# nRF54h20_application register map
Vendor: Nordic Semiconductor; Series: nRF54h; File version: 1
CPU: CM33 r0p4, little endian, MPU, FPU, 3 interrupt priority bits, 480 interrupts, 8 SAU regions
Registers are 32-bit, read-write, reset 0x0 unless marked. A register's access mark holds for its fields unless they carry their own. Offsets are from the block's base; [hi:lo] are bit positions; lines under a group give offsets from that group; 'fields as' and 'values as' point back to an identical list.

## GLOBAL_USBHS_NS — USBHS 0
Base 0x4F086000
Same registers: GLOBAL_USBHS_S 0x5F086000
0x00 TASKS_START wo — Start the USB peripheral.
  [0] TASKS_START
    1=Trigger task
0x04 TASKS_STOP wo — Stop the USB peripheral
  [0] TASKS_STOP
    1=Trigger task
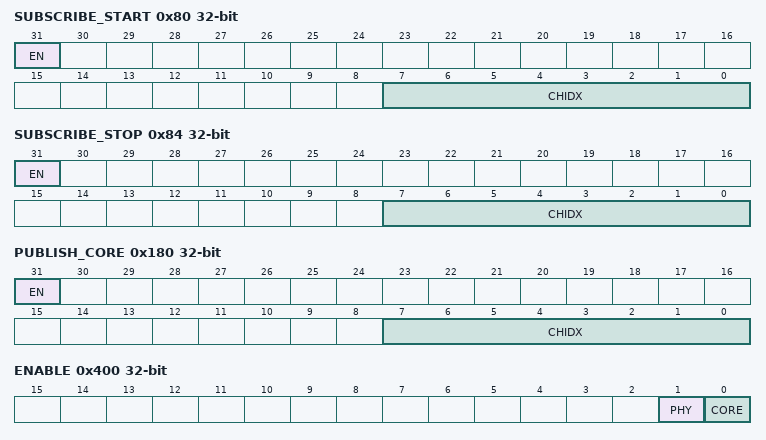
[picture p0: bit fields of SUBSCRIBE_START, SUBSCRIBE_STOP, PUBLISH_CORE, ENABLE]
0x80 SUBSCRIBE_START — Subscribe configuration for task START
  [31] EN
    0=Disabled (Disable subscription); 1=Enabled (Enable subscription)
  [7:0] CHIDX — DPPI channel that task START will subscribe to
0x84 SUBSCRIBE_STOP — Subscribe configuration for task STOP
  [31] EN
    values as SUBSCRIBE_START.EN
  [7:0] CHIDX — DPPI channel that task STOP will subscribe to
0x100 EVENTS_CORE — Event indicating that interrupt triggered at USBHS core
  [0] EVENTS_CORE
    0=NotGenerated (Event not generated); 1=Generated (Event generated)
0x180 PUBLISH_CORE — Publish configuration for event CORE
  [31] EN
    0=Disabled (Disable publishing); 1=Enabled (Enable publishing)
  [7:0] CHIDX — DPPI channel that event CORE will publish to
0x304 INTENSET — Enable interrupt
  [0] CORE — Write '1' to enable interrupt for event CORE
    on read: 0=Disabled (Read: Disabled); 1=Enabled (Read: Enabled) | on write: 1=Set (Enable)
0x308 INTENCLR — Disable interrupt
  [0] CORE — Write '1' to disable interrupt for event CORE
    on read: 0=Disabled (Read: Disabled); 1=Enabled (Read: Enabled) | on write: 1=Clear (Disable)
0x30C INTPEND ro — Pending interrupts
  [0] CORE — Read pending status of interrupt for event CORE
    on read: 0=NotPending (Read: Not pending); 1=Pending (Read: Pending)
0x400 ENABLE — Enable USB peripheral.
  [1] PHY — Enable USB PHY
    0=Disabled (USB PHY disabled.); 1=Enabled (USB PHY enabled.)
  [0] CORE — Enable USB Controller
    0=Disabled (USB Controller disabled.); 1=Enabled (USB Controller enabled.)
0x440 PHY group — Unspecified
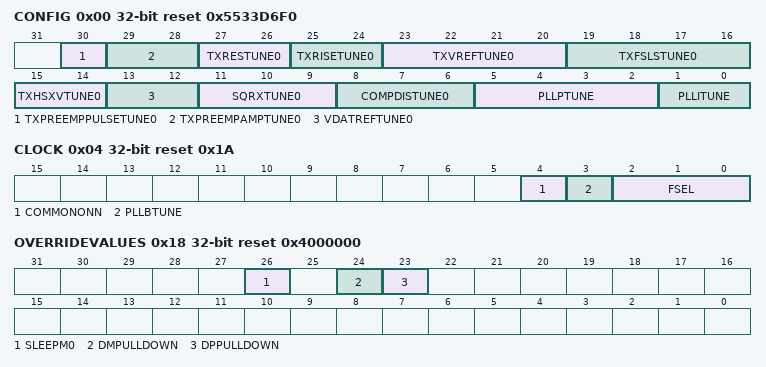
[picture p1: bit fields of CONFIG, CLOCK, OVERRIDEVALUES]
  0x00 CONFIG reset 0x5533D6F0 — USB PHY parameter overrides
    [30] TXPREEMPPULSETUNE0 — HS Transmitter Pre-Emphasis Duration Control
    [29:28] TXPREEMPAMPTUNE0 — HS Transmitter Pre-Emphasis Current Control
    [27:26] TXRESTUNE0 — USB Source Impedance Adjustment
    [25:24] TXRISETUNE0 — HS Transmitter Rise/Fall Time Adjustment
    [23:20] TXVREFTUNE0 — HS DC Voltage Level Adjustment
    [19:16] TXFSLSTUNE0 — FS/LS Source Impedance Adjustment
    [15:14] TXHSXVTUNE0 — Transmitter High-Speed Crossover Adjustment
    [13:12] VDATREFTUNE0 — Data Detect Voltage Adjustment
    [11:9] SQRXTUNE0 — Squelch Threshold Adjustment
    [8:6] COMPDISTUNE0 — Disconnect Threshold Adjustment
    [5:2] PLLPTUNE — PLL Proportional Path Tune
    [1:0] PLLITUNE — PLL Integral Path Tune
  0x04 CLOCK reset 0x1A — USB PHY clock configurations
    [4] COMMONONN — Common block power down control
      0=POWERED (The REFCLOCK_LOGIC,bias and PLL blocks are powered in sleep or suspend mode.); 1=SUSPEND (The REFCLOCK_LOGIC, bias and PLL blocks are powered down in suspend mode and bias and PLL blocks are powered down in sleep mode.)
    [3] PLLBTUNE — PLL bandwidth adjustment
      0=Disabled (PLL bandwidth adjustment disabled.); 1=Enabled (PLL bandwidth adjustment enabled.)
    [2:0] FSEL — Select reference clock frequency
      0=Clock19200KHz (Reference clock is 19.2MHz.); 1=Clock20000KHz (Reference clock is 20MHz.); 2=Clock24000KHz (Reference clock is 24MHz.); 7=Clock50000KHz (Reference clock is 50MHz.)
  0x18 OVERRIDEVALUES reset 0x4000000 — Values that are used to override the input signals to the PHY.
    [26] SLEEPM0
    [24] DMPULLDOWN — This field controls the pull-down resistor on D-
      1=Enable (The pull-down resistor on D+ is enabled); 0=Disable (The pull-down resistor on D+ is disabled)
    [23] DPPULLDOWN — This field controls the pull-down resistor on D+
      values as DMPULLDOWN

## Notices in the file
Copyright (c) 2010 - 2025, Nordic Semiconductor ASA All rights reserved.
SPDX-License-Identifier: BSD-3-Clause
Redistribution and use in source and binary forms, with or without
modification, are permitted provided that the following conditions are met:
1. Redistributions of source code must retain the above copyright notice, this
list of conditions and the following disclaimer.
2. Redistributions in binary form must reproduce the above copyright
notice, this list of conditions and the following disclaimer in the
documentation and/or other materials provided with the distribution.
3. Neither the name of Nordic Semiconductor ASA nor the names of its
contributors may be used to endorse or promote products derived from this
software without specific prior written permission.
THIS SOFTWARE IS PROVIDED BY THE COPYRIGHT HOLDERS AND CONTRIBUTORS "AS IS"
AND ANY EXPRESS OR IMPLIED WARRANTIES, INCLUDING, BUT NOT LIMITED TO, THE
IMPLIED WARRANTIES OF MERCHANTABILITY, AND FITNESS FOR A PARTICULAR PURPOSE
ARE DISCLAIMED. IN NO EVENT SHALL NORDIC SEMICONDUCTOR ASA OR CONTRIBUTORS BE
LIABLE FOR ANY DIRECT, INDIRECT, INCIDENTAL, SPECIAL, EXEMPLARY, OR
CONSEQUENTIAL DAMAGES (INCLUDING, BUT NOT LIMITED TO, PROCUREMENT OF
SUBSTITUTE GOODS OR SERVICES; LOSS OF USE, DATA, OR PROFITS; OR BUSINESS
INTERRUPTION) HOWEVER CAUSED AND ON ANY THEORY OF LIABILITY, WHETHER IN
CONTRACT, STRICT LIABILITY, OR TORT (INCLUDING NEGLIGENCE OR OTHERWISE)
ARISING IN ANY WAY OUT OF THE USE OF THIS SOFTWARE, EVEN IF ADVISED OF THE
POSSIBILITY OF SUCH DAMAGE.
